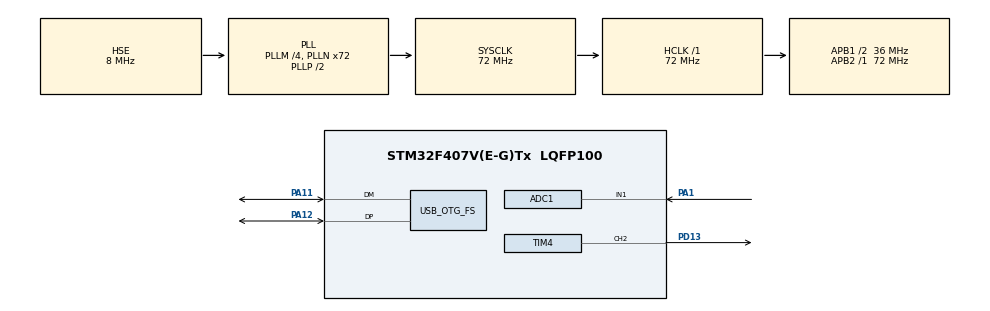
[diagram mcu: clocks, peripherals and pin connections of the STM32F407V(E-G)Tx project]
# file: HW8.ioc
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ADC1.Channel-0\#ChannelRegularConversion=ADC_CHANNEL_1
ADC1.ContinuousConvMode=DISABLE
ADC1.DMAContinuousRequests=ENABLE
ADC1.EnableAnalogWatchDog=false
ADC1.ExternalTrigConv=ADC_EXTERNALTRIGCONV_T2_TRGO
ADC1.NbrOfConversionFlag=1
ADC1.Rank-0\#ChannelRegularConversion=1
ADC1.SamplingTime-0\#ChannelRegularConversion=ADC_SAMPLETIME_3CYCLES
ADC1.master=1
Dma.ADC1.0.Direction=DMA_PERIPH_TO_MEMORY
Dma.ADC1.0.FIFOMode=DMA_FIFOMODE_DISABLE
Dma.ADC1.0.Instance=DMA2_Stream0
Dma.ADC1.0.MemDataAlignment=DMA_MDATAALIGN_HALFWORD
Dma.ADC1.0.MemInc=DMA_MINC_ENABLE
Dma.ADC1.0.Mode=DMA_NORMAL
Dma.ADC1.0.PeriphDataAlignment=DMA_PDATAALIGN_HALFWORD
Dma.ADC1.0.PeriphInc=DMA_PINC_DISABLE
Dma.ADC1.0.Priority=DMA_PRIORITY_LOW
Dma.Request0=ADC1
Dma.Request1=TIM4_CH2
Dma.TIM4_CH2.1.Direction=DMA_MEMORY_TO_PERIPH
Dma.TIM4_CH2.1.FIFOMode=DMA_FIFOMODE_DISABLE
Dma.TIM4_CH2.1.Instance=DMA1_Stream3
Dma.TIM4_CH2.1.MemDataAlignment=DMA_MDATAALIGN_HALFWORD
Dma.TIM4_CH2.1.MemInc=DMA_MINC_ENABLE
Dma.TIM4_CH2.1.Mode=DMA_CIRCULAR
Dma.TIM4_CH2.1.PeriphDataAlignment=DMA_PDATAALIGN_HALFWORD
Dma.TIM4_CH2.1.PeriphInc=DMA_PINC_DISABLE
Dma.TIM4_CH2.1.Priority=DMA_PRIORITY_LOW
FATFS._FS_TINY=0
Mcu.Family=STM32F4
Mcu.Name=STM32F407V(E-G)Tx
Mcu.Package=LQFP100
NVIC.ADC_IRQn=true\:0\:0\:false\:false\:true\:true\:true\:true
NVIC.DMA1_Stream3_IRQn=true\:0\:0\:false\:false\:true\:false\:true\:true
NVIC.DMA2_Stream0_IRQn=true\:0\:0\:false\:false\:true\:false\:true\:true
NVIC.OTG_FS_IRQn=true\:0\:0\:false\:false\:true\:false\:true\:true
NVIC.PriorityGroup=NVIC_PRIORITYGROUP_4
PA1.Signal=ADCx_IN1
PA11.Mode=Device_Only
PA11.Signal=USB_OTG_FS_DM
PA12.Mode=Device_Only
PA12.Signal=USB_OTG_FS_DP
PA13.Mode=Serial_Wire
PA13.Signal=SYS_JTMS-SWDIO
PA14.Mode=Serial_Wire
PA14.Signal=SYS_JTCK-SWCLK
PD13.Signal=S_TIM4_CH2
PH0-OSC_IN.Mode=HSE-External-Oscillator
PH0-OSC_IN.Signal=RCC_OSC_IN
PH1-OSC_OUT.Mode=HSE-External-Oscillator
PH1-OSC_OUT.Signal=RCC_OSC_OUT
ProjectManager.HeapSize=0x200
ProjectManager.StackSize=0x400
ProjectManager.TargetToolchain=CMake
RCC.48MHZClocksFreq_Value=48000000
RCC.AHBFreq_Value=72000000
RCC.APB1CLKDivider=RCC_HCLK_DIV2
RCC.APB1Freq_Value=36000000
RCC.APB1TimFreq_Value=72000000
RCC.APB2Freq_Value=72000000
RCC.APB2TimFreq_Value=72000000
RCC.CortexFreq_Value=72000000
RCC.HCLKFreq_Value=72000000
RCC.HSE_VALUE=8000000
RCC.HSI_VALUE=16000000
RCC.LSE_VALUE=32768
RCC.PLLM=4
RCC.PLLN=72
RCC.PLLQ=3
RCC.SYSCLKFreq_VALUE=72000000
RCC.SYSCLKSource=RCC_SYSCLKSOURCE_PLLCLK
RCC.VCOOutputFreq_Value=144000000
SH.ADCx_IN1.0=ADC1_IN1,IN1
SH.S_TIM4_CH2.0=TIM4_CH2,PWM Generation2 CH2
TIM2.AutoReloadPreload=TIM_AUTORELOAD_PRELOAD_ENABLE
TIM2.Period=99
TIM2.Prescaler=71
TIM2.TIM_MasterOutputTrigger=TIM_TRGO_UPDATE
TIM2.TIM_MasterSlaveMode=TIM_MASTERSLAVEMODE_DISABLE
TIM4.AutoReloadPreload=TIM_AUTORELOAD_PRELOAD_ENABLE
TIM4.Channel-PWM\ Generation2\ CH2=TIM_CHANNEL_2
TIM4.Period=999
TIM4.Prescaler=84-1
USB_DEVICE.CLASS_NAME_FS=MSC
USB_DEVICE.VirtualMode-MSC_FS=Msc
USB_DEVICE.VirtualModeFS=Msc_FS
USB_OTG_FS.VirtualMode=Device_Only
VP_FATFS_VS_Generic.Mode=User_defined
VP_TIM2_VS_ClockSourceINT.Mode=Internal
VP_USB_DEVICE_VS_USB_DEVICE_MSC_FS.Mode=MSC_FS
board=custom

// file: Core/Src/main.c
/* USER CODE BEGIN Header */
/**
  ******************************************************************************
  * @file           : main.c
  * @brief          : Main program body
  ******************************************************************************
  * @attention
  *
  * Copyright (c) 2026 STMicroelectronics.
  * All rights reserved.
  *
  * This software is licensed under terms that can be found in the LICENSE file
  * in the root directory of this software component.
  * If no LICENSE file comes with this software, it is provided AS-IS.
  *
  ******************************************************************************
  */
/* USER CODE END Header */
#include "main.h"
#include "fatfs.h"
#include "usb_device.h"

/* USER CODE BEGIN Includes */
#include "RAMDISK.h"
#include "HW8.h"
/* USER CODE END Includes */

ADC_HandleTypeDef hadc1;
DMA_HandleTypeDef hdma_adc1;

TIM_HandleTypeDef htim2;
TIM_HandleTypeDef htim4;
DMA_HandleTypeDef hdma_tim4_ch2;

void SystemClock_Config(void);
static void MX_GPIO_Init(void);
static void MX_DMA_Init(void);
static void MX_ADC1_Init(void);
static void MX_TIM2_Init(void);
static void MX_TIM4_Init(void);

int main(void)
{

  /* MCU Configuration--------------------------------------------------------*/

  /* Reset of all peripherals, Initializes the Flash interface and the Systick. */
  HAL_Init();

  /* Configure the system clock */
  SystemClock_Config();

  /* Initialize all configured peripherals */
  MX_GPIO_Init();
  MX_DMA_Init();
  MX_ADC1_Init();
  MX_USB_DEVICE_Init();
  MX_TIM2_Init();
  MX_FATFS_Init();
  MX_TIM4_Init();
  /* USER CODE BEGIN 2 */
  HW8_Init();
  /* USER CODE END 2 */

  /* Infinite loop */
  /* USER CODE BEGIN WHILE */
  while (1)
  {
    HW8_Handler();
    /* USER CODE END WHILE */

  }
}

void SystemClock_Config(void)
{
  RCC_OscInitTypeDef RCC_OscInitStruct = {0};
  RCC_ClkInitTypeDef RCC_ClkInitStruct = {0};

  /** Configure the main internal regulator output voltage
  */
  __HAL_RCC_PWR_CLK_ENABLE();
  __HAL_PWR_VOLTAGESCALING_CONFIG(PWR_REGULATOR_VOLTAGE_SCALE1);

  /** Initializes the RCC Oscillators according to the specified parameters
  * in the RCC_OscInitTypeDef structure.
  */
  RCC_OscInitStruct.OscillatorType = RCC_OSCILLATORTYPE_HSE;
  RCC_OscInitStruct.HSEState = RCC_HSE_ON;
  RCC_OscInitStruct.PLL.PLLState = RCC_PLL_ON;
  RCC_OscInitStruct.PLL.PLLSource = RCC_PLLSOURCE_HSE;
  RCC_OscInitStruct.PLL.PLLM = 4;
  RCC_OscInitStruct.PLL.PLLN = 72;
  RCC_OscInitStruct.PLL.PLLP = RCC_PLLP_DIV2;
  RCC_OscInitStruct.PLL.PLLQ = 3;
  if (HAL_RCC_OscConfig(&RCC_OscInitStruct) != HAL_OK)
  {
    Error_Handler();
  }

  /** Initializes the CPU, AHB and APB buses clocks
  */
  RCC_ClkInitStruct.ClockType = RCC_CLOCKTYPE_HCLK|RCC_CLOCKTYPE_SYSCLK
                              |RCC_CLOCKTYPE_PCLK1|RCC_CLOCKTYPE_PCLK2;
  RCC_ClkInitStruct.SYSCLKSource = RCC_SYSCLKSOURCE_PLLCLK;
  RCC_ClkInitStruct.AHBCLKDivider = RCC_SYSCLK_DIV1;
  RCC_ClkInitStruct.APB1CLKDivider = RCC_HCLK_DIV2;
  RCC_ClkInitStruct.APB2CLKDivider = RCC_HCLK_DIV1;

  if (HAL_RCC_ClockConfig(&RCC_ClkInitStruct, FLASH_LATENCY_2) != HAL_OK)
  {
    Error_Handler();
  }
}

static void MX_ADC1_Init(void)
{

  ADC_ChannelConfTypeDef sConfig = {0};

  /** Configure the global features of the ADC (Clock, Resolution, Data Alignment and number of conversion)
  */
  hadc1.Instance = ADC1;
  hadc1.Init.ClockPrescaler = ADC_CLOCK_SYNC_PCLK_DIV2;
  hadc1.Init.Resolution = ADC_RESOLUTION_12B;
  hadc1.Init.ScanConvMode = DISABLE;
  hadc1.Init.ContinuousConvMode = DISABLE;
  hadc1.Init.DiscontinuousConvMode = DISABLE;
  hadc1.Init.ExternalTrigConvEdge = ADC_EXTERNALTRIGCONVEDGE_RISING;
  hadc1.Init.ExternalTrigConv = ADC_EXTERNALTRIGCONV_T2_TRGO;
  hadc1.Init.DataAlign = ADC_DATAALIGN_RIGHT;
  hadc1.Init.NbrOfConversion = 1;
  hadc1.Init.DMAContinuousRequests = ENABLE;
  hadc1.Init.EOCSelection = ADC_EOC_SINGLE_CONV;
  if (HAL_ADC_Init(&hadc1) != HAL_OK)
  {
    Error_Handler();
  }

  /** Configure for the selected ADC regular channel its corresponding rank in the sequencer and its sample time.
  */
  sConfig.Channel = ADC_CHANNEL_1;
  sConfig.Rank = 1;
  sConfig.SamplingTime = ADC_SAMPLETIME_3CYCLES;
  if (HAL_ADC_ConfigChannel(&hadc1, &sConfig) != HAL_OK)
  {
    Error_Handler();
  }

}

static void MX_TIM2_Init(void)
{

  TIM_ClockConfigTypeDef sClockSourceConfig = {0};
  TIM_MasterConfigTypeDef sMasterConfig = {0};

  htim2.Instance = TIM2;
  htim2.Init.Prescaler = 71;
  htim2.Init.CounterMode = TIM_COUNTERMODE_UP;
  htim2.Init.Period = 99;
  htim2.Init.ClockDivision = TIM_CLOCKDIVISION_DIV1;
  htim2.Init.AutoReloadPreload = TIM_AUTORELOAD_PRELOAD_ENABLE;
  if (HAL_TIM_Base_Init(&htim2) != HAL_OK)
  {
    Error_Handler();
  }
  sClockSourceConfig.ClockSource = TIM_CLOCKSOURCE_INTERNAL;
  if (HAL_TIM_ConfigClockSource(&htim2, &sClockSourceConfig) != HAL_OK)
  {
    Error_Handler();
  }
  sMasterConfig.MasterOutputTrigger = TIM_TRGO_UPDATE;
  sMasterConfig.MasterSlaveMode = TIM_MASTERSLAVEMODE_DISABLE;
  if (HAL_TIMEx_MasterConfigSynchronization(&htim2, &sMasterConfig) != HAL_OK)
  {
    Error_Handler();
  }

}

static void MX_TIM4_Init(void)
{

  TIM_MasterConfigTypeDef sMasterConfig = {0};
  TIM_OC_InitTypeDef sConfigOC = {0};

  htim4.Instance = TIM4;
  htim4.Init.Prescaler = 84-1;
  htim4.Init.CounterMode = TIM_COUNTERMODE_UP;
  htim4.Init.Period = 999;
  htim4.Init.ClockDivision = TIM_CLOCKDIVISION_DIV1;
  htim4.Init.AutoReloadPreload = TIM_AUTORELOAD_PRELOAD_ENABLE;
  if (HAL_TIM_PWM_Init(&htim4) != HAL_OK)
  {
    Error_Handler();
  }
  sMasterConfig.MasterOutputTrigger = TIM_TRGO_RESET;
  sMasterConfig.MasterSlaveMode = TIM_MASTERSLAVEMODE_DISABLE;
  if (HAL_TIMEx_MasterConfigSynchronization(&htim4, &sMasterConfig) != HAL_OK)
  {
    Error_Handler();
  }
  sConfigOC.OCMode = TIM_OCMODE_PWM1;
  sConfigOC.Pulse = 0;
  sConfigOC.OCPolarity = TIM_OCPOLARITY_HIGH;
  sConfigOC.OCFastMode = TIM_OCFAST_DISABLE;
  if (HAL_TIM_PWM_ConfigChannel(&htim4, &sConfigOC, TIM_CHANNEL_2) != HAL_OK)
  {
    Error_Handler();
  }
  HAL_TIM_MspPostInit(&htim4);

}

static void MX_DMA_Init(void)
{

  /* DMA controller clock enable */
  __HAL_RCC_DMA2_CLK_ENABLE();
  __HAL_RCC_DMA1_CLK_ENABLE();

  /* DMA interrupt init */
  /* DMA1_Stream3_IRQn interrupt configuration */
  HAL_NVIC_SetPriority(DMA1_Stream3_IRQn, 0, 0);
  HAL_NVIC_EnableIRQ(DMA1_Stream3_IRQn);
  /* DMA2_Stream0_IRQn interrupt configuration */
  HAL_NVIC_SetPriority(DMA2_Stream0_IRQn, 0, 0);
  HAL_NVIC_EnableIRQ(DMA2_Stream0_IRQn);

}

static void MX_GPIO_Init(void)
{

  /* GPIO Ports Clock Enable */
  __HAL_RCC_GPIOH_CLK_ENABLE();
  __HAL_RCC_GPIOA_CLK_ENABLE();
  __HAL_RCC_GPIOD_CLK_ENABLE();

}

void Error_Handler(void)
{
  __disable_irq();
  while (1)
  {
  }
}
